# SYSTIM register map
Vendor: Texas Instruments
Peripheral module from a debugger description file (folder CC27xxx15).
Registers are 32-bit, access per field, reset values left out (the file's numbers can be read two ways) unless marked. A register's access mark holds for its fields unless they carry their own. Offsets are as the file gives them; lines under a group give offsets from that group; [hi:lo] are bit positions; {n}, {i} and the like mark numbered series; 'fields as' and 'values as' point back to an identical list; <NAME> marks a mode.

## SYSTIM — SVT System Timer Module
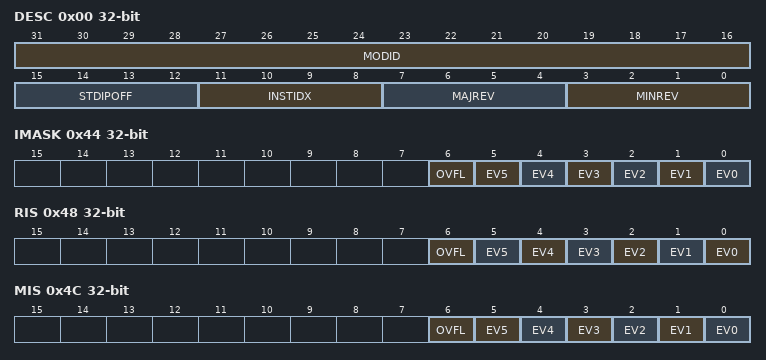
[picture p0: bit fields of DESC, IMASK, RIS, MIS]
0x00 DESC ro — Description. This register identifies the peripheral and its exact version.
  [31:16] MODID — Module identifier used to uniquely identify this IP.
  [15:12] STDIPOFF — Standard IP MMR block offset. Standard IP MMRs are the set of from aggregated IRQ registers till DTB. 0: Standard IP MMRs do not exist 0x1-0xF: Standard IP MMRs begin at offset of (64*STDIPOFF from the base IP address)
  [11:8] INSTIDX — IP Instance ID number. If multiple instances of IP exists in SOC, this field can identify the instance number 0-15
  [7:4] MAJREV — Major revision of IP 0-15
  [3:0] MINREV — Minor revision of IP 0-15.
0x44 IMASK — Interrupt mask. This register selects interrupt sources which are allowed to pass from RIS to MIS when the corresponding bit-fields are set to 1.
  [all] fields
    1=EN (Enable Interrrupt Mask); 0=DIS (Disable Interrupt Mask)
  [6] OVFL rw — Systimer counter overflow event interrupt mask.
  [n] EV{n} rw (n=0..5) — Systimer channel {n} event interrupt mask.
0x48 RIS ro — Raw interrupt status. This register reflects the state of all pending interrupts, regardless of masking. This register allows the user to implement a poll scheme. A flag set in this register can be cleared by writing 1 to the corresponding ICLR register bit.
  [all] fields
    1=SET (Interrupt occured); 0=CLR (Interrupt did not occur)
  [6] OVFL — Raw interrupt status for Systimer counter overflow event. This bit is set to 1 when an event is received on SysTimer Overflow occurs.
  [5] EV5 — Raw interrupt status for channel 5 event. This bit is set to 1 when a CAPTURE or COMPARE event is received on channel 5.
  [4] EV4 — Raw interrupt status for channel 4 event. This bit is set to 1 when a CAPTURE or COMPARE event is received on channel 4.
  [3] EV3 — Raw interrupt status for channel 3 event. This bit is set to 1 when a CAPTURE or COMPARE event is received on channel 3.
  [2] EV2 — Raw interrupt status for channel 2 Event. This bit is set to 1 when a CAPTURE or COMPARE event is received on channel 2.
  [1] EV1 — Raw interrupt status for channel 1 event. This bit is set to 1 when a CAPTURE or COMPARE event is received on channel 1.
  [0] EV0 — Raw interrupt status for channel 0 event. This bit is set to 1 when a CAPTURE or COMPARE event is received on channel 0.
0x4C MIS ro — Masked interrupt status. This register is simply a bitwise AND of the contents of IMASK and RIS.*] registers. A flag set in this register can be cleared by writing 1 to the corresponding ICLR register bit.
  [all] fields
    1=SET (Interrupt occured); 0=CLR (Interrupt did not occur)
  [6] OVFL — Mask Interrupt status for Systimer counter overflow Event in MIS register.
  [n] EV{n} (n=0..5) — Mask interrupt status for channel {n} event.
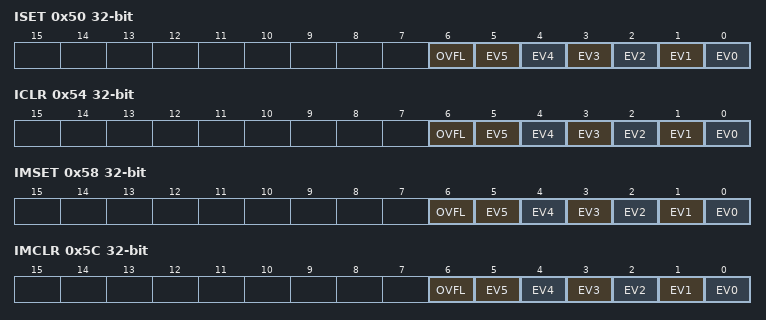
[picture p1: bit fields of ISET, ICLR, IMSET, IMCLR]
0x50 ISET — Interrupt set. This register can used by software for diagnostics and safety checking purposes. Writing a 1 to a bit in this register will set the event and the corresponding RIS bit also gets set. If the corresponding IMASK bit is set, then the corresponding MIS register bit also gets set.
  [all] fields
    1=SET (Set Interrupt); 0=NOEFF (Writing 0 has no effect)
  [6] OVFL wo — Sets Systimer counter overflow interrupt.
  [n] EV{n} wo (n=0..5) — Sets channel {n} interrupt.
0x54 ICLR — Interrupt clear. 'This register allows software to clear interrupts. Writing a 1 to a bit in this register will clear the event and the corresponding RIS bit also gets cleared. If the corresponding IMASK bit is set, then the corresponding MIS register bit also gets cleared.
  [all] fields
    1=CLR (Clear Interrupt); 0=NOEFF (Writing 0 has no effect)
  [6] OVFL wo — Clears Systimer counter overflow interrupt.
  [n] EV{n} wo (n=0..5) — Clears channel {n} interrupt.
0x58 IMSET — Interrupt mask set. Writing a 1 to a bit in this register will set the corresponding IMASK bit.
  [all] fields
    1=SET (Set interrupt mask); 0=NOEFF (Writing 0 has no effect)
  [6] OVFL wo — Sets Timer Overflow Event Interrupt Mask.
  [n] EV{n} wo (n=0..5) — Sets channel{n} Event Interrupt mask
0x5C IMCLR — Interrupt mask clear. Writing a 1 to a bit in this register will clear the corresponding IMASK bit.
  [all] fields
    1=CLR (Clear interrupt mask); 0=NOEFF (Writing 0 has no effect)
  [6] OVFL wo — Clears Timer Overflow Event Interrupt Mask.
  [n] EV{n} wo (n=0..5) — Clears channel{n} Event Interrupt Mask.
0x60 EMU — Emulation control. This register controls the behavior of the IP related to core halted input.
  [0] HALT rw — Halt control.
    1=STOP (Freeze option. The IP freezes functionality when the core halted input is asserted, and resumes when it is deasserted. The freeze can either be immediate or after the IP has reached a boundary from where it can resume without corruption.); 0=RUN (Free run option. The IP ignores the state of the core halted input.)
0x100 TIME250N ro — Systimer Counter Value - 250ns resolution. This 32-bit value reads out bits [31:0] of the systimer counter. The counter is 34-bit and runs on CLKSVT/12. It maintains a resolution of 250ns with a range of about 17.9m.
  [31:0] VAL — 32-bit counter value [31:0]. This will provide a 250ns resolution and a range of 17.9m.
0x104 TIME1U ro — Systimer Counter Value - 1μs resolution This 32-bit value reads out bits[33:2] of the systimer counter. The counter is 34-bit and runs on CLKSVT/12. It maintains a resolution of 1us with a range of about 1 h 11m.
  [31:0] VAL — 32-bit counter value [33:2]. This will provide a resolution of 1us and a range of 1hr and 11m.
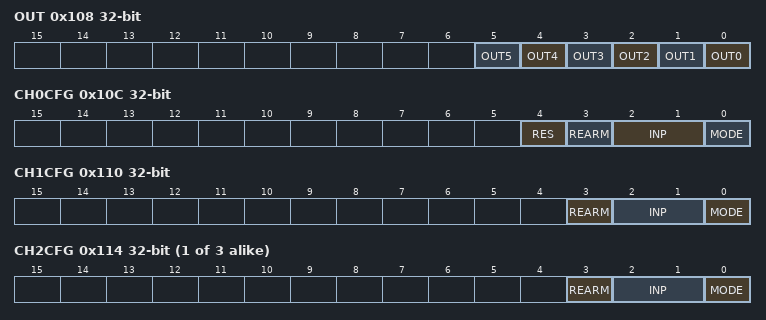
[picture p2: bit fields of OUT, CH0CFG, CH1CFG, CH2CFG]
0x108 OUT ro — Systimer's channel Output Event Values
  [all] fields
    1=SET (Event occured); 0=CLR (Event did not occur.)
  [n] OUT{n} (n=0..5) — Output Value of channel {n}.
0x10C CH0CFG — Systimer channel 0 configuration. This channel has configurability for 250ns and 1us based capture and compare operations.
  [4] RES rw — This bit decides the RESOLUTION of the channel that will be used.
    1=NS (channel Works in Timer's 250ns resolution); 0=US (channel Works in Timer's 1us Resolution.)
  [3] REARM rw — When Rearm is enabled the channel remains in continous capture mode. Otherwise it'll be in one shot capture mode. Rearm is only valid for capture mode.
    1=EN (Re arm is enabled); 0=DIS (Re Arm is disabled)
  [2:1] INP rw — Decides the channel input signal's mode. Setting the Value as 2'b11 selects the Rise Function.
    2=BOTH (Capture on both Edge); 1=FALL (Capture on Falling Edge); 0=RISE (Capture on rising edge)
  [0] MODE rw — Decides the channel mode.
    1=CAPT (channel is in capture mode); 0=DIS (channel is disabled)
0x110 CH1CFG — Systimer channel 1 configuration. This channel works in 1us based capture and compare operations.
  [3] REARM rw — When Rearm is enabled the channel remains in continous capture mode. Otherwise it'll be in one shot capture mode. Rearm is only valid for capture mode.
    1=EN (Re arm is enabled); 0=DIS (Re Arm is disabled)
  [2:1] INP rw — Decides the channel input signal's mode. Setting the Value as 2'b11 selects the Rise Function
    values as CH0CFG.INP
  [0] MODE rw — Decides the channel mode.
    values as CH0CFG.MODE
{0x10C+4i} CH{i}CFG (i=2..4) — Systimer channel {i} configuration. This channel works in 250ns based capture and compare operations.
  fields as CH1CFG
{0x120+4i} CH{i}CC rw (i=0..4) — System Timer channel {i} Capture/Compare register. This register when written with any compare value will arm the channel to work in compare mode. Reads to this register will clear the Corresponding RIS.EV{i} bit.
  [31:0] VAL — Capture/compare value
0x134 TIMEBIT — Systimer's Time bit. This Register will be used to specify which TIME bit is required by LGPT to be forwarded from SYSTIMER.
  [15:0] VAL rw — The corresponding bit will have value '1' rest should be '0'. If more than one bit is asserted, output is "or" of all the bits.
    0x8000=BIT17 (Bit17 is forwarded to the event fabric.); 0x4000=BIT16 (Bit16 is forwarded to the event fabric.); 0x2000=BIT15 (Bit15 is forwarded to the event fabric.); 0x1000=BIT14 (Bit14 is forwarded to the event fabric.); 0x800=BIT13 (Bit13 is forwarded to the event fabric.); 0x400=BIT12 (Bit12 is forwarded to the event fabric.); 0x200=BIT11 (Bit11 is forwarded to the event fabric.); 0x100=BIT10 (Bit10 is forwarded to the event fabric.); 128=BIT9 (Bit9 is forwarded to the event fabric.); 64=BIT8 (Bit8 is forwarded to the event fabric.); 32=BIT7 (Bit7 is forwarded to the event fabric.); 16=BIT6 (Bit6 is forwarded to the event fabric.); 8=BIT5 (Bit5 is forwarded to the event fabric.); 4=BIT4 (Bit4 is forwarded to the event fabric.); 2=BIT3 (Bit3 is forwarded to the event fabric.); 1=BIT2 (Bit2 is forwarded to the event fabric.); 0=NOBIT (No bit is forwarded to the event fabric.)
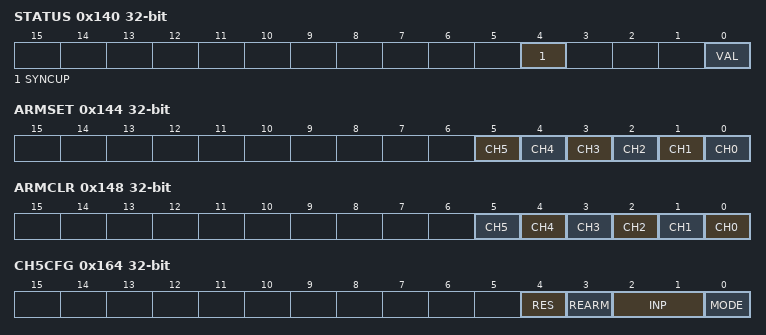
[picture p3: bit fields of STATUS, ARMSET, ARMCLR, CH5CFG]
0x140 STATUS — Systimer status. This register can be used to read the running status of the timer and to resync the Systimer with RTC.
  [4] SYNCUP rw — This bit indicates sync status of Systimer with RTC. The bitfield has a reset value of '1', which gets cleared to '0' after the Systimer synchronizes with RTC on the first LFTICK edge. A write to this bit resynchronizes the Systimer with RTC on the next LFTICK edge. A read value of '1' indicates the synchronization is ongoing and a read of '0' indicates the synchronization is done.
  [0] VAL ro — This bit indicates if the system time is initialized and running.
    1=RUN (system timer is running); 0=STOP (system timer is not running.)
0x144 ARMSET — ARMSET Reading this register gives out the status of the 5 channels. Channel state UNARMED returns 0. Channel state CAPTURE or COMPARE returns 1. A write to ARMSET has for each channel the following effect - If ARMSTA[x]==0 -$gt; no effect If ARMSTA[x]==1 and channel x is in CAPTURE state then no effect on the channel Else, set channel in COMPARE mode using existing CHxVAL value
  [5] CH5 rw — Arming channel 5 for either compare or capture operation.
    1=SET (if channel 5 is in CAPTURE state then no effect on the channel else it can set channel in COMPARE mode using existing CH4CC.VAL value.); 0=NOEFF (No effect on the channel)
  [4] CH4 rw — Arming channel 4 for either compare or capture operation.
    1=SET (if channel 4 is in CAPTURE state then no effect on the channel else it can set channel in COMPARE mode using existing CH4CC.VAL value.); 0=NOEFF (No effect on the channel)
  [3] CH3 rw — Arming channel 3 for either compare or capture operation.
    1=SET (if channel 3 is in CAPTURE state then no effect on the channel else it can set channel in COMPARE mode using existing CH3CC.VAL value); 0=NOEFF (No effect on the channel)
  [2] CH2 rw — Arming channel 2 for either compare or capture operation.
    1=SET (if channel 2 is in CAPTURE state then no effect on the channel else it can set channel in COMPARE mode using existing CH2CC.VAL value); 0=NOEFF (No effect on the channel)
  [1] CH1 rw — Arming channel 1 for either compare or capture operation.
    1=SET (if channel 1 is in CAPTURE state then no effect on the channel else it can Set channel in COMPARE mode using existing CH1CC.VAL value); 0=NOEFF (No effect on the channel)
  [0] CH0 rw — Arming channel 0 for either compare or capture operation.
    1=SET (if channel 0 is in CAPTURE state then no effect on the channel else it can set channel in COMPARE mode using existing CH0CC.VAL value); 0=NOEFF (No effect on the channel)
0x148 ARMCLR — ARMCLR Read of this register gives out the status of the 5 channels . Channel state UNARMED returns 0. Channel state CAPTURE or COMPARE returns 1. A write to ARMCLR has for each channel the following effect - If ARMCLR[x]==0 -$gt; no effect. Else, set channel in UNARMED state without triggering event unless a compare/capture event happens in the same cycle
  [all] fields
    1=CLR (Set channel in UNARMED state without triggering event unless a compare/capture event happens in the same cycle); 0=NOEFF (No effect on the channel)
  [n] CH{n} rw (n=0..5) — Disarming channel {n}
0x14C CH0CCSR rw — Save/restore alias register for channel 0. A read to this register, will give out the value of register CH0CC. Moreover, reads to this register will not have any effects on RIS.EV0 or configuration of the channel. Write to CH0CCSR sets CH0CC.VAL value of register without affecting channel state or configuration
  [31:0] VAL — Capture/compare value
{0x14C+4i} CH{i}CCSR rw (i=1..5) — Save/restore alias register for channel {i}. A read to this register, will give out the value of register CH{i}CC. Moreover, reads to this register will not have any effects on RIS.EV{i} or configuration of the channel. Write to CH{i}CCSR sets CH{i}CC.VAL value of register without affecting channel state or configuration.
  [31:0] VAL — Capture/compare value
0x164 CH5CFG — Systimer channel 5 configuration. This channel has configurability for 250ns and 1us based capture and compare operations.
  fields as CH0CFG
0x168 CH5CC rw — System Timer channel 5 Capture/Compare register. This register when written with any compare value will arm the channel to work in compare mode. Reads to this register will clear the Corresponding RIS.EV5 bit.
  [31:0] VAL — Capture/compare value
